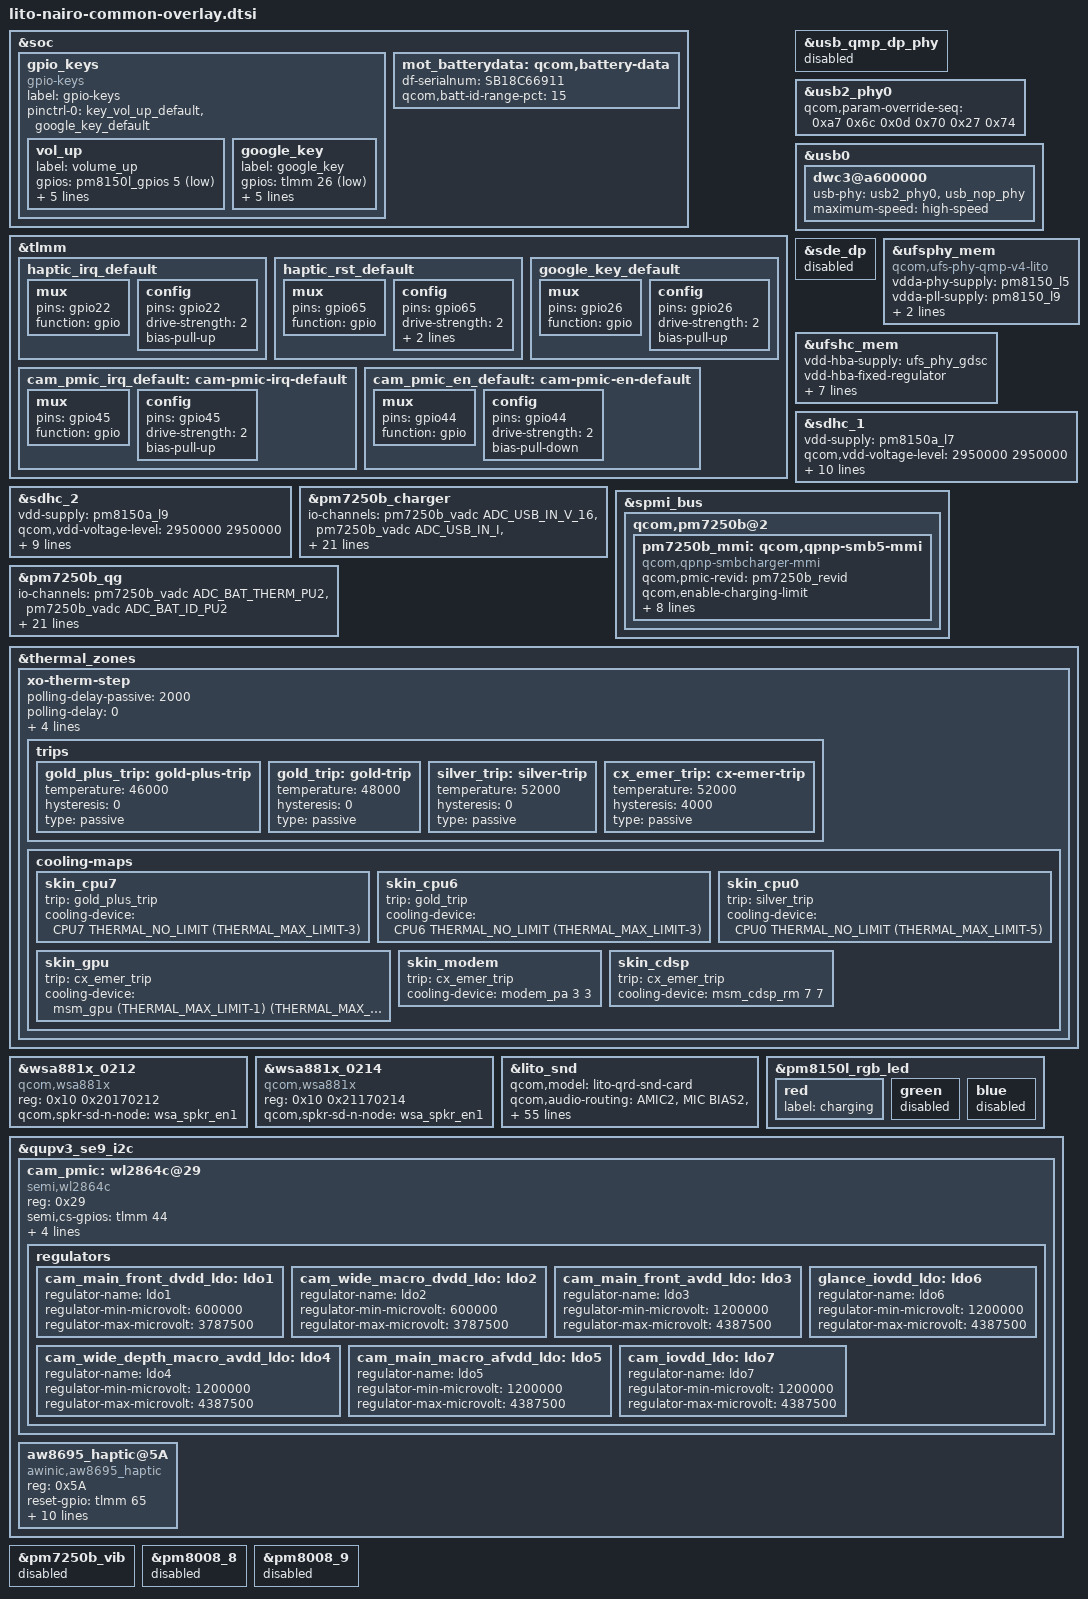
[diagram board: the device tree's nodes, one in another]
/* Copyright (c) 2019, The Linux Foundation. All rights reserved.
 *
 * This program is free software; you can redistribute it and/or modify
 * it under the terms of the GNU General Public License version 2 and
 * only version 2 as published by the Free Software Foundation.
 *
 * This program is distributed in the hope that it will be useful,
 * but WITHOUT ANY WARRANTY; without even the implied warranty of
 * MERCHANTABILITY or FITNESS FOR A PARTICULAR PURPOSE.  See the
 * GNU General Public License for more details.
 */

#include <dt-bindings/interrupt-controller/arm-gic.h>
#include <dt-bindings/gpio/gpio.h>
#include "lito-pmic-overlay.dtsi"
#include "lito-audio-overlay.dtsi"
#include "lito-thermal-overlay.dtsi"
#include "lito-nairo-nfc.dtsi"
#include "lito-moto-nairobi-display.dtsi"
#include "lito-nairo-touchscreen.dtsi"
#include "lito-nairo-fingerprint.dtsi"

#include "lito-nairo-audio-overlay.dtsi"
#include "lito-nairo-sensor-overlay.dtsi"
#include "lito-nairo-thermal.dtsi"
#include "lito-moto-common-overlay.dtsi"


&soc {
	gpio_keys {
		compatible = "gpio-keys";
		label = "gpio-keys";

		pinctrl-names = "default";
		pinctrl-0 = <&key_vol_up_default &google_key_default>;

		vol_up {
			label = "volume_up";
			gpios = <&pm8150l_gpios 5 GPIO_ACTIVE_LOW>;
			linux,input-type = <1>;
			linux,code = <KEY_VOLUMEUP>;
			gpio-key,wakeup;
			debounce-interval = <15>;
			linux,can-disable;
		};

		google_key {
			label = "google_key";
			gpios = <&tlmm 26 GPIO_ACTIVE_LOW>;
			linux,input-type = <1>;
			linux,code = <KEY_HOME>;
			gpio-key,wakeup;
			debounce-interval = <15>;
			linux,can-disable;
		};
	};

	mot_batterydata: qcom,battery-data {
		df-serialnum = "SB18C66911";
		qcom,batt-id-range-pct = <15>;
		#include "qg-batterydata-lr50-atl-4500mah.dtsi"
	};
};

&tlmm {
	haptic_irq_default: haptic_irq_default {
		mux {
			pins = "gpio22";
			function = "gpio";
		};

		config {
			pins = "gpio22";
			drive-strength = <2>; /* 2 MA */
			bias-pull-up;
		};
	};

	haptic_rst_default: haptic_rst_default {
		mux {
			pins = "gpio65";
			function = "gpio";
		};

		config {
			pins = "gpio65";
			drive-strength = <2>; /* 2 MA */
			bias-disable;
			output-low;
		};
	};

	google_key_default: google_key_default {
		mux {
			pins = "gpio26";
			function = "gpio";
		};

		config {
			pins = "gpio26";
			drive-strength = <2>;
			bias-pull-up;
		};
	};
};

&usb_qmp_dp_phy {
	status = "disabled";
};

&usb2_phy0 {
	qcom,param-override-seq =
		<0xa7 0x6c
		0x0d 0x70
		0x27 0x74>;
};

&usb0 {
	dwc3@a600000 {
		usb-phy = <&usb2_phy0>, <&usb_nop_phy>;
		maximum-speed = "high-speed";
	};
};

&sde_dp {
	status = "disabled";
};

&ufsphy_mem {
	compatible = "qcom,ufs-phy-qmp-v4-lito";

	vdda-phy-supply = <&pm8150_l5>;
	vdda-pll-supply = <&pm8150_l9>;
	vdda-phy-max-microamp = <90200>;
	vdda-pll-max-microamp = <19000>;

	status = "ok";
};

&ufshc_mem {
	vdd-hba-supply = <&ufs_phy_gdsc>;
	vdd-hba-fixed-regulator;
	vcc-supply = <&pm8150a_l7>;
	vcc-voltage-level = <2950000 2960000>;
	vccq2-supply = <&pm8150_s4>;
	vcc-max-microamp = <800000>;
	vccq2-max-microamp = <800000>;

	qcom,vddp-ref-clk-supply = <&pm8150_l9>;
	qcom,vddp-ref-clk-max-microamp = <100>;

	status = "ok";
};

&sdhc_1 {
	vdd-supply = <&pm8150a_l7>;
	qcom,vdd-voltage-level = <2950000 2950000>;
	qcom,vdd-current-level = <0 570000>;

	vdd-io-supply = <&pm8150_s4>;
	qcom,vdd-io-always-on;
	qcom,vdd-io-lpm-sup;
	qcom,vdd-io-voltage-level = <1800000 1800000>;
	qcom,vdd-io-current-level = <0 325000>;

	pinctrl-names = "active", "sleep";
	pinctrl-0 = <&sdc1_clk_on &sdc1_cmd_on &sdc1_data_on
					&sdc1_rclk_on>;
	pinctrl-1 = <&sdc1_clk_off &sdc1_cmd_off &sdc1_data_off
					&sdc1_rclk_off>;

	status = "ok";
};

&sdhc_2 {
	vdd-supply = <&pm8150a_l9>;
	qcom,vdd-voltage-level = <2950000 2950000>;
	qcom,vdd-current-level = <0 800000>;

	vdd-io-supply = <&pm8150a_l6>;
	qcom,vdd-io-voltage-level = <1800000 2950000>;
	qcom,vdd-io-current-level = <0 22000>;

	pinctrl-names = "active", "sleep";
	pinctrl-0 = <&sdc2_clk_on  &sdc2_cmd_on &sdc2_data_on &sdc2_cd_on>;
	pinctrl-1 = <&sdc2_clk_off &sdc2_cmd_off &sdc2_data_off &sdc2_cd_off>;

	cd-gpios = <&tlmm 69 GPIO_ACTIVE_HIGH>;

	status = "ok";
};


&pm7250b_charger {
	status = "ok";
	io-channels = <&pm7250b_vadc ADC_USB_IN_V_16>,
		      <&pm7250b_vadc ADC_USB_IN_I>,
		      <&pm7250b_vadc ADC_CHG_TEMP>,
		      <&pm7250b_vadc ADC_DIE_TEMP>,
		      <&pm7250b_vadc ADC_AMUX_THM3_PU2>,
		      <&pm7250b_vadc ADC_SBUx>,
		      <&pm7250b_vadc ADC_VPH_PWR>;
	io-channel-names = "usb_in_voltage",
			   "usb_in_current",
			   "chg_temp",
			   "die_temp",
			   "conn_temp",
			   "sbux_res",
			   "vph_voltage";
	qcom,battery-data = <&mot_batterydata>;
	qcom,sec-charger-config = <0>;
	qcom,auto-recharge-soc = <99>;
	qcom,charger-temp-max = <800>;
	qcom,smb-temp-max = <800>;
        qcom,fcc-max-ua = <3600000>;
        qcom,fv-max-uv = <4450000>;
        qcom,usb-icl-ua = <3000000>;
        qcom,thermal-mitigation = <3600000 2500000
                        2000000 1500000
                        1200000 900000
                        600000 300000>;
        qcom,typec-legacy-rp-icl;
        qcom,lpd-disable;
	qcom,suspend-input-on-debug-batt;
	qcom,disable-suspend-on-collapse;
	qcom,pd-voltage-max-uv = <9000000>;
	qcom,usbpd-phandle = <&pm7250b_pdphy>;
};

&spmi_bus {
	qcom,pm7250b@2 {
		pm7250b_mmi: qcom,qpnp-smb5-mmi {
			status = "ok";
			compatible = "qcom,qpnp-smbcharger-mmi";
			qcom,pmic-revid = <&pm7250b_revid>;
			qcom,enable-charging-limit;
			qcom,upper-limit-capacity = <75>;
			qcom,lower-limit-capacity = <60>;
			qcom,mmi-temp-zones = <0 4200 880 0>,
						<10 4200 2185 880>,
						<15 0 2185 2185>,
						<45 4200 3600 2185>,
						<60 4200 2185 0>;
			qcom,iterm-ma = <110>;
			qcom,vfloat-comp-uv = <20000>;
			qcom,force-hvdcp-5v;
		};
	};
};

&pm7250b_qg {
	status = "ok";
	io-channels = <&pm7250b_vadc ADC_BAT_THERM_PU2>,
		      <&pm7250b_vadc ADC_BAT_ID_PU2>;
	io-channel-names = "batt-therm",
			   "batt-id";
	qcom,battery-data = <&mot_batterydata>;
	qcom,hold-soc-while-full;
	qcom,linearize-soc;
	qcom,qg-use-s7-ocv;
	qcom,qg-iterm-ma = <250>;
	qcom,vbatt-cutoff-mv = <3200>;
	qcom,vbatt-empty-mv = <3000>;
	qcom,vbatt-empty-cold-mv = <3000>;
	qcom,rbat-conn-mohm = <10>;
	qcom,cl-feedback-on;
	qcom,cl-min-start-soc = <0>;
	qcom,cl-max-start-soc = <5>;
	qcom,cl-min-temp = <150>;
	qcom,cl-max-temp = <450>;
	qcom,cl-max-increment = <5>;
	qcom,cl-max-decrement = <10>;
	qcom,cl-min-limit = <200>;
	qcom,cl-max-limit = <30>;
	qcom,s3-entry-ibat-ua = <15000>;
	qcom,s3-exit-ibat-ua = <35000>;
	qcom,s3-entry-fifo-length = <2>;

};

&thermal_zones {
	xo-therm-step {
		polling-delay-passive = <2000>;
		polling-delay = <0>;
		thermal-governor = "step_wise";
		thermal-sensors = <&pm8150_adc_tm ADC_XO_THERM_PU2>;
		wake-capable-sensor;
		trips {
			gold_plus_trip: gold-plus-trip {
				temperature = <46000>;
				hysteresis = <0>;
				type = "passive";
			};

			gold_trip: gold-trip {
				temperature = <48000>;
				hysteresis = <0>;
				type = "passive";
			};

			silver_trip: silver-trip {
				temperature = <52000>;
				hysteresis = <0>;
				type = "passive";
			};

			cx_emer_trip: cx-emer-trip {
				temperature = <52000>;
				hysteresis = <4000>;
				type = "passive";
			};
		};

		cooling-maps {
			skin_cpu7 {
				trip = <&gold_plus_trip>;
					/* throttle from fmax to 1516800KHz */
				cooling-device =
					<&CPU7 THERMAL_NO_LIMIT
						(THERMAL_MAX_LIMIT-3)>;
			};

			skin_cpu6 {
				trip = <&gold_trip>;
					/* throttle from fmax to 1478400KHz */
				cooling-device =
					<&CPU6 THERMAL_NO_LIMIT
						(THERMAL_MAX_LIMIT-3)>;
			};

			skin_cpu0 {
				trip = <&silver_trip>;
					/* throttle from fmax to 1459200KHz */
				cooling-device = <&CPU0 THERMAL_NO_LIMIT
						(THERMAL_MAX_LIMIT-5)>;
			};

			skin_gpu {
				trip = <&cx_emer_trip>;
				cooling-device = <&msm_gpu (THERMAL_MAX_LIMIT-1)
						(THERMAL_MAX_LIMIT-1)>;
			};

			skin_modem {
				trip = <&cx_emer_trip>;
				cooling-device = <&modem_pa 3 3>;
			};

			skin_cdsp {
				trip = <&cx_emer_trip>;
				cooling-device = <&msm_cdsp_rm 7 7>;
			};
		};
	};
};

&wsa881x_0212 {
	compatible = "qcom,wsa881x";
	reg = <0x10 0x20170212>;
	qcom,spkr-sd-n-node = <&wsa_spkr_en1>;
};

&wsa881x_0214 {
	compatible = "qcom,wsa881x";
	reg = <0x10 0x21170214>;
	qcom,spkr-sd-n-node = <&wsa_spkr_en1>;
};

&lito_snd {
	qcom,model = "lito-qrd-snd-card";
	qcom,audio-routing =
		"AMIC2", "MIC BIAS2",
		"MIC BIAS2", "Analog Mic2",
		"TX DMIC0", "MIC BIAS3",
		"MIC BIAS3", "Digital Mic0",
		"TX DMIC1", "MIC BIAS3",
		"MIC BIAS3", "Digital Mic1",
		"TX DMIC2", "MIC BIAS1",
		"MIC BIAS1", "Digital Mic2",
		"TX DMIC3", "MIC BIAS1",
		"MIC BIAS1", "Digital Mic3",
		"TX DMIC4", "MIC BIAS4",
		"MIC BIAS4", "Digital Mic4",
		"TX DMIC5", "MIC BIAS4",
		"MIC BIAS4", "Digital Mic5",
		"IN1_HPHL", "HPHL_OUT",
		"IN2_HPHR", "HPHR_OUT",
		"IN3_AUX", "AUX_OUT",
		"TX SWR_ADC0", "ADC1_OUTPUT",
		"TX SWR_ADC1", "ADC2_OUTPUT",
		"TX SWR_ADC2", "ADC3_OUTPUT",
		"TX SWR_ADC3", "ADC4_OUTPUT",
		"TX SWR_DMIC0", "DMIC1_OUTPUT",
		"TX SWR_DMIC1", "DMIC2_OUTPUT",
		"TX SWR_DMIC2", "DMIC3_OUTPUT",
		"TX SWR_DMIC3", "DMIC4_OUTPUT",
		"TX SWR_DMIC4", "DMIC5_OUTPUT",
		"TX SWR_DMIC5", "DMIC6_OUTPUT",
		"TX SWR_DMIC6", "DMIC7_OUTPUT",
		"TX SWR_DMIC7", "DMIC8_OUTPUT",
		"WSA SRC0_INP", "SRC0",
		"WSA_TX DEC0_INP", "TX DEC0 MUX",
		"WSA_TX DEC1_INP", "TX DEC1 MUX",
		"RX_TX DEC0_INP", "TX DEC0 MUX",
		"RX_TX DEC1_INP", "TX DEC1 MUX",
		"RX_TX DEC2_INP", "TX DEC2 MUX",
		"RX_TX DEC3_INP", "TX DEC3 MUX",
		"SpkrRight IN", "WSA_SPK2 OUT",
		"VA_AIF1 CAP", "VA_SWR_CLK",
		"VA_AIF2 CAP", "VA_SWR_CLK",
		"VA_AIF3 CAP", "VA_SWR_CLK",
		"VA MIC BIAS3", "Digital Mic0",
		"VA MIC BIAS3", "Digital Mic1",
		"VA MIC BIAS1", "Digital Mic2",
		"VA MIC BIAS1", "Digital Mic3",
		"VA MIC BIAS4", "Digital Mic4",
		"VA MIC BIAS4", "Digital Mic5",
		"VA DMIC0", "VA MIC BIAS3",
		"VA DMIC1", "VA MIC BIAS3",
		"VA DMIC2", "VA MIC BIAS1",
		"VA DMIC3", "VA MIC BIAS1",
		"VA DMIC4", "VA MIC BIAS4",
		"VA DMIC5", "VA MIC BIAS4",
		"VA SWR_ADC0", "VA_SWR_CLK",
		"VA SWR_ADC1", "VA_SWR_CLK",
		"VA SWR_ADC2", "VA_SWR_CLK",
		"VA SWR_ADC3", "VA_SWR_CLK",
		"VA SWR_MIC0", "VA_SWR_CLK",
		"VA SWR_MIC1", "VA_SWR_CLK",
		"VA SWR_MIC2", "VA_SWR_CLK",
		"VA SWR_MIC3", "VA_SWR_CLK",
		"VA SWR_MIC4", "VA_SWR_CLK",
		"VA SWR_MIC5", "VA_SWR_CLK",
		"VA SWR_MIC6", "VA_SWR_CLK",
		"VA SWR_MIC7", "VA_SWR_CLK",
		"VA SWR_ADC1", "ADC2_OUTPUT",
		"VA SWR_MIC0", "DMIC1_OUTPUT",
		"VA SWR_MIC1", "DMIC2_OUTPUT",
		"VA SWR_MIC0", "DMIC1_OUTPUT",
		"VA SWR_MIC1", "DMIC2_OUTPUT",
		"VA SWR_MIC2", "DMIC3_OUTPUT",
		"VA SWR_MIC3", "DMIC4_OUTPUT",
		"VA SWR_MIC4", "DMIC5_OUTPUT",
		"VA SWR_MIC5", "DMIC6_OUTPUT",
		"VA SWR_MIC6", "DMIC7_OUTPUT",
		"VA SWR_MIC7", "DMIC8_OUTPUT";
	qcom,wsa-max-devs = <1>;
	qcom,wsa-devs = <&wsa881x_0212>, <&wsa881x_0214>;
	qcom,wsa-aux-dev-prefix = "SpkrRight", "SpkrRight";
	qcom,msm-mbhc-usbc-audio-supported = <1>;
	qcom,msm-mbhc-hphl-swh = <0>;
	qcom,msm-mbhc-gnd-swh = <0>;
};

&pm8150l_rgb_led {
	red {
		label = "charging";
	};

	green {
		status = "disabled";
	};

	blue {
		status = "disabled";
	};
};

&tlmm{
	cam_pmic_irq_default: cam-pmic-irq-default {
		mux {
			pins = "gpio45";
			function = "gpio";
		};
		config {
		        pins = "gpio45";
			drive-strength = <2>; /* 2 mA */
			bias-pull-up;
		};
	};

	cam_pmic_en_default: cam-pmic-en-default {
		mux {
			pins = "gpio44";
			function = "gpio";
		};
		config {
			pins = "gpio44";
			drive-strength = <2>;
			bias-pull-down;
		};
	};
};

&qupv3_se9_i2c {
	status = "ok";

	cam_pmic: wl2864c@29{
		compatible = "semi,wl2864c";
		reg = <0x29>;

		semi,cs-gpios = <&tlmm 44 0>;

		pinctrl-names = "default";
		pinctrl-0 = <&cam_pmic_irq_default &cam_pmic_en_default>;

		vin1-supply = <&pm8150a_s8>;
		vin2-supply = <&pm8150a_bob>;

		regulators {
			cam_main_front_dvdd_ldo: ldo1 {
				regulator-name = "ldo1";
				regulator-min-microvolt = <600000>;
				regulator-max-microvolt = <3787500>;
			};

			cam_wide_macro_dvdd_ldo: ldo2 {
				regulator-name = "ldo2";
				regulator-min-microvolt = <600000>;
				regulator-max-microvolt = <3787500>;
			};

			cam_main_front_avdd_ldo: ldo3 {
				regulator-name = "ldo3";
				regulator-min-microvolt = <1200000>;
				regulator-max-microvolt = <4387500>;
			};

			cam_wide_depth_macro_avdd_ldo: ldo4 {
				regulator-name = "ldo4";
				regulator-min-microvolt = <1200000>;
				regulator-max-microvolt = <4387500>;
			};

			cam_main_macro_afvdd_ldo: ldo5 {
				regulator-name = "ldo5";
				regulator-min-microvolt = <1200000>;
				regulator-max-microvolt = <4387500>;
			};

			glance_iovdd_ldo: ldo6 {
				regulator-name = "ldo6";
				regulator-min-microvolt = <1200000>;
				regulator-max-microvolt = <4387500>;
			};

			cam_iovdd_ldo: ldo7 {
				regulator-name = "ldo7";
				regulator-min-microvolt = <1200000>;
				regulator-max-microvolt = <4387500>;
			};
		};
	};

	aw8695_haptic@5A {
		compatible = "awinic,aw8695_haptic";
		reg = <0x5A>;
		reset-gpio = <&tlmm 65 0>;
		irq-gpio = <&tlmm 22 0>;
		vib_f0_pre = < 2350 >;
		vib_f0_cali_percen = < 7 >;
		vib_cont_drv_lvl = < 110 >;
		vib_cont_drv_lvl_ov = < 120 >;
		vib_cont_td = < 0x006C >;
		vib_cont_zc_thr = < 0x0FF1 >;
		vib_cont_num_brk = < 3 >;
		pinctrl-names = "default";
		pinctrl-0 = <&haptic_irq_default &haptic_rst_default>;
		status = "okay";
	};
};

&pm7250b_vib {
	status = "disabled";
};

&pm8008_8 {
	status = "disabled";
};

&pm8008_9 {
	status = "disabled";
};
